# STM32MP25_CA35 register map
File version: 1.3
Registers are 32-bit, read-write, reset 0x0 unless marked. A register's access mark holds for its fields unless they carry their own. Offsets are from the block's base; [hi:lo] are bit positions; {n}, {i} and the like mark numbered series.

## STGENR — System timer generator
Base 0x58070000
Same registers: STGENR_S 0x48070000
0x00 STGENR_CNTCVL ro — STGENR value lower register
  [31:0] CNTCVL_L_32 — current value of the timestamp counter (the lower 32 bits)
0x04 STGENR_CNTCVU ro — STGENR value upper register
  [31:0] CNTCVU_U_32 — current value of the timestamp counter (the upper 32 bits)
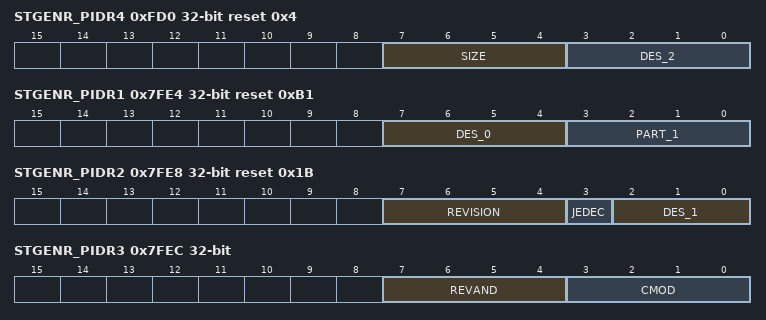
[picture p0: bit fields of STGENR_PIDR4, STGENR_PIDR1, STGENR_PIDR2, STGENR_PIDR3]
0xFD0 STGENR_PIDR4 ro reset 0x4 — STGENR peripheral ID4 register
  [7:4] SIZE — always 0b0000 Indicates that the device only occupies 4 Kbytes of memory.
  [3:0] DES_2 — part of designer identification Together STGEN_PIDR1.DES_0, STGEN_PIDR2.DES_1, and STGEN_PIDR4.DES_2 identify the designer of the component.
{0xFC0+4i} STGENR_PIDR{i} ro (i=5..7) — STGENR peripheral ID{i} register
  [31:0] PIDR{i} — peripheral ID{i}
0x7FE0 STGENR_PIDR0 ro reset 0x1 — STGENR peripheral ID0 register
  [7:0] PART_0 — bits[7:0] of the 12-bit part number of the component.
0x7FE4 STGENR_PIDR1 ro reset 0xB1 — STGENR peripheral ID1 register
  [7:4] DES_0 — part of designer identification Together STGEN_PIDR1.DES_0, STGEN_PIDR2.DES_1, and STGEN_PIDR4.DES_2 identify the designer of the component.
  [3:0] PART_1 — Bits[11:8] of the 12-bit part number of the component
0x7FE8 STGENR_PIDR2 ro reset 0x1B — STGENR peripheral ID2 register
  [7:4] REVISION — device revision number
  [3] JEDEC — always 1 Indicates that the JEDEC-assigned designer ID is used.
  [2:0] DES_1 — part of designer identification Together STGEN_PIDR1.DES_0, STGEN_PIDR2.DES_1, and STGEN_PIDR4.DES_2, identify the designer of the component.
0x7FEC STGENR_PIDR3 ro — STGENR peripheral ID3 register
  [7:4] REVAND — errata fix identification 0b0000 indicates there are no errata fixes to this component.
  [3:0] CMOD — customer modified Indicates whether the customer has modified the behavior of the component. In most cases, this field is 0b0000 (no modification done). Customers change this value when they make authorized modifications to this component.
0x7FF0 STGENR_CIDR0 ro reset 0xD — STGENR component ID0 register
  [7:0] PRMBL_0 — preamble 0 Contains bits[7:0] of the component identification code.
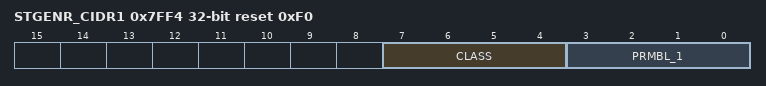
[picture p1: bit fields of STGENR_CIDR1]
0x7FF4 STGENR_CIDR1 ro reset 0xF0 — STGENR component ID1 register
  [7:4] CLASS — class of the component Contains bits[15:12] of the component identification code.
  [3:0] PRMBL_1 — preamble 1 Contains bits[11:8] of the component identification code.
0x7FF8 STGENR_CIDR2 ro reset 0x50 — STGENR component ID2 register
  [7:0] PRMBL_2 — preamble 2 Contains bits[23:16] of the component identification code.
0x7FFC STGENR_CIDR3 ro reset 0xB1 — STGENR component ID3 register
  [7:0] PRMBL_3 — preamble 3 Contains bits[31:24] of the component identification code.

## OCTOSPIM — OCTOSPIM register block
Base 0x40500000
Same registers: OCTOSPIM_S 0x50500000
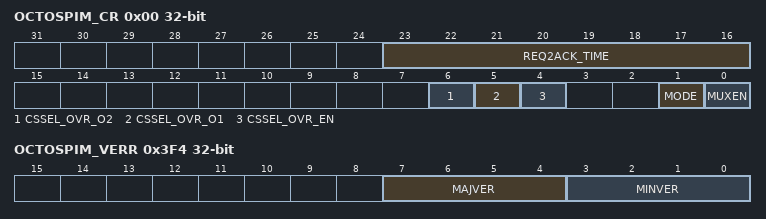
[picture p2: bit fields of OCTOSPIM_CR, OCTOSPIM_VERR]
0x00 OCTOSPIM_CR — OCTOSPIM control register
  [23:16] REQ2ACK_TIME — REQ to ACK time In multiplexed mode (MUXEN = 1), this field defines the time between two transactions. The value is the number of OCTOSPI clock cycles - 1
  [6] CSSEL_OVR_O2 — Chip select selector override setting for OCTOSPI2
    0=the chip select signal from OCTOSPI2 is sent to NCS1; 1=the chip select signal from OCTOSPI2 is sent to NCS2
  [5] CSSEL_OVR_O1 — Chip select selector override setting for OCTOSPI1
    0=the chip select signal from OCTOSPI1 is sent to NCS1; 1=the chip select signal from OCTOSPI1 is sent to NCS2
  [4] CSSEL_OVR_EN — Chip select selector override enable
    0=override not enabled; 1=CSSEL_OVR_O1 and CSSEL_OVR_O2 bit values overwrite the CSSEL signal values coming from OCTOSPI1 and OCTOSPI2
  [1] MODE — OCTOSPIM multiplexing mode
    0=if MUXEN = 0 direct mode, if MUXEN = 1 arbitration mode to output Port 1; 1=if MUXEN = 0 swapped mode, if MUXEN = 1 arbitration mode to output Port 2
  [0] MUXEN — Multiplexed mode enable This bit enables the multiplexing of the two OCTOSPIs.
    0=No multiplexing, hence no arbitration; 1=OCTOSPI1 and OCTOSPI2 are multiplexed over the same bus
0x3F0 OCTOSPIM_HWCFGR ro reset 0x2 — OCTOSPIM hardware configuration register
  [3:0] NUM_PORT — Number of ports This field returns the number of ports in the OCTOSPI I/O manager implementation
0x3F4 OCTOSPIM_VERR ro (reset mask 0xFFFFFF00) — OCTOSPIM version register
  [7:4] MAJVER — OCTOSPIM major version
  [3:0] MINVER — OCTOSPIM minor version
0x3F8 OCTOSPIM_IDR ro reset 0x141041 — OCTOSPIM identification
  [31:0] ID
0x3FC OCTOSPIM_SIDR ro reset 0xA3C5DD01 — OCTOSPIM size identification register
  [31:0] SID — Size identifier This field returns the size of the memory region allocated to registers. The address decoding range is 1 Kbyte.
